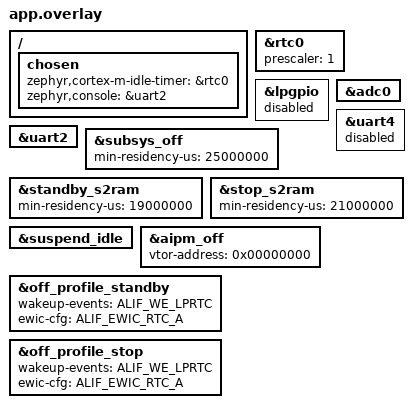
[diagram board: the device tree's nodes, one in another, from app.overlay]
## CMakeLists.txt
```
# Copyright (C) 2026 Alif Semiconductor - All Rights Reserved.
# Use, distribution and modification of this code is permitted under the
# terms stated in the Alif Semiconductor Software License Agreement
#
# You should have received a copy of the Alif Semiconductor Software
# License Agreement with this file. If not, please write to:
# contact@alifsemi.com, or visit: https://alifsemi.com/license

cmake_minimum_required(VERSION 3.20.0)
find_package(Zephyr REQUIRED HINTS $ENV{ZEPHYR_BASE})
project(adc_pm)

target_sources(app PRIVATE src/main.c)
```

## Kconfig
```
# Copyright (C) 2026 Alif Semiconductor - All Rights Reserved.
# Use, distribution and modification of this code is permitted under the
# terms stated in the Alif Semiconductor Software License Agreement
#
# You should have received a copy of the Alif Semiconductor Software
# License Agreement with this file. If not, please write to:
# contact@alifsemi.com, or visit: https://alifsemi.com/license

mainmenu "Alif ADC Power Management Demo"

source "Kconfig.zephyr"
```

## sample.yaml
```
sample:
  name: Alif ADC Power Management Demo
  description: >
    Demonstrates Zephyr power management states (PM_STATE_RUNTIME_IDLE,
    PM_STATE_SUSPEND_TO_IDLE, PM_STATE_SUSPEND_TO_RAM, PM_STATE_SOFT_OFF)
    for Alif RTSS cores with ADC12 temperature-sensor conversions between
    PM state transitions. PM states exercised are selected via build
    snippets: adc-pm-s2ram-tcm (HE TCM retention) and adc-pm-mram
    (MRAM boot SOFT_OFF, HE or HP).
common:
  tags:
    - power
    - pm
    - adc
    - counter
    - rtc
    - drivers
  filter: SOC_FAMILY_ENSEMBLE or SOC_FAMILY_BALLETTO
  harness: console
  harness_config:
    type: multi_line
    regex:
      - "ADC PM demo"
      - "POWER STATE SEQUENCE"
tests:
  sample.drivers.adc.pm.s2ram_tcm:
    platform_allow:
      - alif_e7_dk_rtss_he
      - alif_e8_dk_rtss_he
      - alif_e1c_dk_rtss_he
      - alif_b1_dk_rtss_he
    integration_platforms:
      - alif_e7_dk_rtss_he
    depends_on:
      - counter
      - adc
    extra_args:
      - SNIPPET=adc-pm-s2ram-tcm
  sample.drivers.adc.pm.mram:
    platform_allow:
      - alif_e7_dk_rtss_he
      - alif_e7_dk_rtss_hp
      - alif_e8_dk_rtss_he
      - alif_e8_dk_rtss_hp
      - alif_e1c_dk_rtss_he
      - alif_b1_dk_rtss_he
    integration_platforms:
      - alif_e7_dk_rtss_he
      - alif_e7_dk_rtss_hp
    depends_on:
      - counter
      - adc
    extra_args:
      - SNIPPET=adc-pm-mram
```

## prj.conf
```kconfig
# Copyright (C) 2026 Alif Semiconductor - All Rights Reserved.
# Use, distribution and modification of this code is permitted under the
# terms stated in the Alif Semiconductor Software License Agreement
#
# You should have received a copy of the Alif Semiconductor Software
# License Agreement with this file. If not, please write to:
# contact@alifsemi.com, or visit: https://alifsemi.com/license

CONFIG_ADC=y
CONFIG_USE_ALIF_HAL_ANALOG=y
CONFIG_CBPRINTF_FP_SUPPORT=y

CONFIG_PM=y
CONFIG_PM_DEVICE=y
CONFIG_POWER_DOMAIN=y
CONFIG_IDLE_STACK_SIZE=1024
CONFIG_SYS_CLOCK_TICKS_PER_SEC=1000

CONFIG_COUNTER=y

CONFIG_STDOUT_CONSOLE=y
CONFIG_PRINTK=y
CONFIG_ASSERT=y

CONFIG_LOG=y
CONFIG_LOG_DEFAULT_LEVEL=0
CONFIG_LOG_MODE_DEFERRED=y
CONFIG_LOG_PROCESS_THREAD_SLEEP_MS=5
CONFIG_LOG_BACKEND_UART=y
```

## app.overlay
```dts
/* Copyright (C) 2025 Alif Semiconductor - All Rights Reserved.
 * Use, distribution and modification of this code is permitted under the
 * terms stated in the Alif Semiconductor Software License Agreement
 *
 * You should have received a copy of the Alif Semiconductor Software
 * License Agreement with this file. If not, please write to:
 * contact@alifsemi.com, or visit: https://alifsemi.com/license
 *
 */

&rtc0 {
	prescaler = <1>;
	status = "okay";
};

&lpgpio {
	status = "disabled";
};

&adc0 {
	status = "okay";
};

&uart4 {
	status = "disabled";
};

&uart2 {
	status = "okay";
};

&subsys_off {
	min-residency-us = <25000000>;
	status = "okay";
};

&standby_s2ram {
	min-residency-us = <19000000>;
	status = "okay";
};

&stop_s2ram {
	min-residency-us = <21000000>;
	status = "okay";
};

&suspend_idle {
	status = "okay";
};

&aipm_off {
	vtor-address = <0x00000000>;
	status = "okay";
};

&off_profile_standby {
	status = "okay";
	wakeup-events = <ALIF_WE_LPRTC>;
	ewic-cfg = <ALIF_EWIC_RTC_A>;
};

&off_profile_stop {
	status = "okay";
	wakeup-events = <ALIF_WE_LPRTC>;
	ewic-cfg = <ALIF_EWIC_RTC_A>;
};

/ {
	chosen {
		zephyr,cortex-m-idle-timer = &rtc0;
		zephyr,console = &uart2;
	};
};
```

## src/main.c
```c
/* Copyright (C) 2026 Alif Semiconductor - All Rights Reserved.
 * Use, distribution and modification of this code is permitted under the
 * terms stated in the Alif Semiconductor Software License Agreement
 *
 * You should have received a copy of the Alif Semiconductor Software
 * License Agreement with this file. If not, please write to:
 * contact@alifsemi.com, or visit: https://alifsemi.com/license
 *
 */

 #include <stdio.h>
 #include <zephyr/kernel.h>
 #include <zephyr/device.h>
 #include <zephyr/devicetree.h>
 #include <zephyr/init.h>
 #include <zephyr/pm/pm.h>
 #include <zephyr/pm/policy.h>
 #include <zephyr/drivers/adc.h>
 #include <zephyr/drivers/counter.h>
 #include <zephyr/sys/util.h>
 #include <zephyr/logging/log.h>
 #include "temperature.h"

 LOG_MODULE_REGISTER(pm_adc, LOG_LEVEL_INF);

 /* Set to 1 to dump full NVIC ISPR state on wakeup */
 #define APP_PM_WAKEUP_DEBUG 0

 #define ADC_DEV_NODE DT_NODELABEL(adc0)

 #define ADC_CHANNEL_6			(0x06)
 #define ADC_UNMASK_CHANNEL_6		(1 << 6)

 /* Number of ADC conversions per PM phase */
 #define ADC_NUM_READS 3

 #if DT_NODE_HAS_COMPAT_STATUS(DT_NODELABEL(rtc0), snps_dw_apb_rtc, okay)
	 #define WAKEUP_SOURCE DT_NODELABEL(rtc0)
 #elif DT_NODE_HAS_COMPAT_STATUS(DT_NODELABEL(timer0), snps_dw_timers, okay)
	 #define WAKEUP_SOURCE DT_NODELABEL(timer0)
 #else
 #error "Wakeup Device not enabled in the dts"
 #endif

 /*
  * Sleep duration constants for each PM state.
  *
  * Upper bound: at 400 MHz, ticks-to-cycles calculation in the PM driver
  * overflows uint32 max for values > 10.7s (2^32 / 400). Deep-sleep durations
  * (S2RAM, SOFT_OFF) and overlay min-residency-us values must stay below this
  * ceiling. RUNTIME_IDLE may exceed it because deeper states are locked out
  * during that sleep (see app_pm_lock_sleep_states()).
  */
 /* Sleep duration for PM_STATE_RUNTIME_IDLE */
 #define RUNTIME_IDLE_SLEEP_USEC (18 * 1000 * 1000)
 /* Sleep duration for PM_STATE_SUSPEND_TO_IDLE */
 #define SUSPEND_IDLE_SLEEP_USEC (10 * 1000)
 /* Sleep duration for PM_STATE_SUSPEND_TO_RAM substate 0 (STANDBY) */
 #define S2RAM_STANDBY_SLEEP_USEC (6 * 1000 * 1000)
 /* Sleep duration for PM_STATE_SUSPEND_TO_RAM substate 1 (STOP) */
 #define S2RAM_STOP_SLEEP_USEC (9 * 1000 * 1000)
 /* Sleep duration for PM_STATE_SOFT_OFF */
 #define SOFT_OFF_SLEEP_USEC (10 * 1000 * 1000)

 /*
  * MRAM base address - used to determine boot location
  * TCM boot: VTOR = 0x0
  * MRAM boot: VTOR >= 0x80000000
  */
 #define MRAM_BASE_ADDRESS 0x80000000

 #define IS_BOOTING_FROM_MRAM() (SCB->VTOR >= MRAM_BASE_ADDRESS)

 /*
  * True when the DTS chosen zephyr,sram points at sram0. The snippet overlay
  * is responsible for ensuring SRAM0 has retention support on the target board.
  */
 #if DT_NODE_EXISTS(DT_NODELABEL(sram0)) && DT_HAS_CHOSEN(zephyr_sram)
 #define IS_SRAM0_CONFIGURED_AS_RAM() \
	 DT_SAME_NODE(DT_CHOSEN(zephyr_sram), DT_NODELABEL(sram0))
 #else
 #define IS_SRAM0_CONFIGURED_AS_RAM() 0
 #endif

 /*
  * S2RAM_SUPPORTED — retention-capable sleep is possible when:
  *   - SRAM0 is the configured data RAM (HE or HP, E8 only), OR
  *   - HE core booting from TCM (TCM has hardware retention)
  *
  * SOFT_OFF_SUPPORTED — mutually exclusive with S2RAM: used when no
  * retained RAM is available (HP-TCM, HE-MRAM boot without SRAM0).
  */
 #define S2RAM_SUPPORTED \
	 (IS_SRAM0_CONFIGURED_AS_RAM() || \
	  (IS_ENABLED(CONFIG_RTSS_HE) && !IS_BOOTING_FROM_MRAM()))

 #define SOFT_OFF_SUPPORTED (!S2RAM_SUPPORTED)

 /* Validate ordering of deep-sleep durations at compile time */
 BUILD_ASSERT(S2RAM_STOP_SLEEP_USEC > S2RAM_STANDBY_SLEEP_USEC,
	 "STOP sleep duration must be greater than STANDBY sleep duration");
 BUILD_ASSERT(SOFT_OFF_SLEEP_USEC > S2RAM_STOP_SLEEP_USEC,
	 "SOFT_OFF sleep duration must be greater than STOP sleep duration");

 /**
  * Helper function to lock/unlock deeper power states.
  * @param lock true → lock all deep states (allow RUNTIME_IDLE only)
  *             false → unlock the applicable state; keep the other locked
  */
 static void app_pm_lock_deeper_states(bool lock)
 {
	 if (lock) {
		 pm_policy_state_lock_get(PM_STATE_SUSPEND_TO_RAM, PM_ALL_SUBSTATES);
		 pm_policy_state_lock_get(PM_STATE_SOFT_OFF,       PM_ALL_SUBSTATES);
	 } else {
		 pm_policy_state_lock_put(PM_STATE_SOFT_OFF,       PM_ALL_SUBSTATES);
		 pm_policy_state_lock_put(PM_STATE_SUSPEND_TO_RAM, PM_ALL_SUBSTATES);
	 }
 }

 /*
  * Lock every PM sleep state deeper than RUNTIME_IDLE. Intended for use around
  * ADC conversions and around any sleep call the app makes where an accidental
  * upgrade to a deeper state must be prevented.
  *
  * ADC IRQs sit outside the IWIC wakeup range, so SUSPEND_TO_IDLE must not be
  * entered while a conversion is in progress.
  */
 static void app_pm_lock_sleep_states(bool lock)
 {
	 if (lock) {
		 pm_policy_state_lock_get(PM_STATE_SUSPEND_TO_IDLE, PM_ALL_SUBSTATES);
		 pm_policy_state_lock_get(PM_STATE_SUSPEND_TO_RAM,  PM_ALL_SUBSTATES);
		 pm_policy_state_lock_get(PM_STATE_SOFT_OFF,        PM_ALL_SUBSTATES);
	 } else {
		 pm_policy_state_lock_put(PM_STATE_SOFT_OFF,        PM_ALL_SUBSTATES);
		 pm_policy_state_lock_put(PM_STATE_SUSPEND_TO_RAM,  PM_ALL_SUBSTATES);
		 pm_policy_state_lock_put(PM_STATE_SUSPEND_TO_IDLE, PM_ALL_SUBSTATES);
	 }
 }

 #if !defined(CONFIG_CORTEX_M_SYSTICK_LPM_TIMER_COUNTER)
 static volatile uint32_t alarm_cb_status;
 static void alarm_callback_fn(const struct device *wakeup_dev,
				 uint8_t chan_id, uint32_t ticks,
				 void *user_data)
 {
	 LOG_DBG("%s: Alarm triggered", wakeup_dev->name);
	 alarm_cb_status = 1;
 }
 #endif

 static int app_enter_normal_sleep(uint32_t sleep_usec)
 {
 #if defined(CONFIG_CORTEX_M_SYSTICK_LPM_TIMER_COUNTER)
	 k_sleep(K_USEC(sleep_usec));
 #else
	 const struct device *const wakeup_dev = DEVICE_DT_GET(WAKEUP_SOURCE);
	 struct counter_alarm_cfg alarm_cfg = {0};
	 int ret;

	 alarm_cfg.flags = 0;
	 alarm_cfg.ticks = counter_us_to_ticks(wakeup_dev, sleep_usec);
	 alarm_cfg.callback = alarm_callback_fn;
	 alarm_cfg.user_data = &alarm_cfg;

	 ret = counter_set_channel_alarm(wakeup_dev, 0, &alarm_cfg);
	 if (ret) {
		 LOG_ERR("Could not set the alarm");
		 return ret;
	 }
	 LOG_DBG("Set alarm for %u microseconds", sleep_usec);

	 k_sleep(K_USEC(sleep_usec));

	 if (!alarm_cb_status) {
		 return -1;
	 }
	 alarm_cb_status = 0;

 #endif
	 return 0;
 }

 static int app_enter_deep_sleep(uint32_t sleep_usec)
 {
 #if defined(CONFIG_CORTEX_M_SYSTICK_LPM_TIMER_COUNTER)
	 /*
	  * Set a delay more than the min-residency-us configured so that
	  * the sub-system will go to OFF state.
	  */
	 k_sleep(K_USEC(sleep_usec));
 #else
	 const struct device *const wakeup_dev = DEVICE_DT_GET(WAKEUP_SOURCE);
	 struct counter_alarm_cfg alarm_cfg = {0};
	 int ret;
	 /*
	  * Set the alarm and delay so that idle thread can run
	  */
	 alarm_cfg.ticks = counter_us_to_ticks(wakeup_dev, sleep_usec);
	 ret = counter_set_channel_alarm(wakeup_dev, 0, &alarm_cfg);
	 if (ret) {
		 LOG_ERR("Failed to set the alarm (err %d)", ret);
		 return ret;
	 }

	 LOG_DBG("Set alarm for %u microseconds", sleep_usec);
	 /*
	  * Wait for the alarm to trigger. The idle thread will
	  * take care of entering the deep sleep state via PM framework.
	  */
	 k_sleep(K_USEC(sleep_usec));
 #endif

	 return 0;
 }

 static uint32_t adc_buffer[1];
 static uint32_t m_samplings_done;
 static uint8_t comparator;

 enum adc_action adc_call_back(const struct device *dev,
				 const struct adc_sequence *sequence,
				 uint16_t sampling_index)
 {
	 ARG_UNUSED(dev);
	 ARG_UNUSED(sequence);
	 ARG_UNUSED(sampling_index);

	 ++m_samplings_done;

	 if (m_samplings_done < 2) {
		 return ADC_ACTION_REPEAT;
	 }

	 return ADC_ACTION_FINISH;
 }

 /*
  * Re-setup the TSENS channel and take one conversion. Channel setup is
  * repeated after each resume because adc_hw_init() rebuilds analog state.
  */
 static int adc_read_once(const struct device *adc_dev)
 {
	 struct adc_sequence_options adc_seq_options = {
		 .callback = adc_call_back,
		 .user_data = &comparator,
	 };
	 struct adc_channel_cfg channel_cfg = {
		 .differential = 0,
		 .channel_id = ADC_CHANNEL_6,
	 };
	 struct adc_sequence sequence = {
		 .options = &adc_seq_options,
		 .buffer = adc_buffer,
		 .buffer_size = sizeof(adc_buffer),
		 .channels = ADC_UNMASK_CHANNEL_6,
	 };
	 float temp;
	 int ret;

	 m_samplings_done = 0;

	 ret = adc_channel_setup(adc_dev, &channel_cfg);
	 if (ret) {
		 LOG_ERR("Unable to set up ADC channel %u (err %d)",
			 channel_cfg.channel_id, ret);
		 return ret;
	 }

	 ret = adc_read(adc_dev, &sequence);
	 if (ret) {
		 LOG_ERR("ADC read failed (err %d)", ret);
		 return ret;
	 }

	 temp = get_temperature(adc_buffer[0]);
	 if (temp == -1) {
		 LOG_INF("ADC raw=0x%X (temperature outside range)", adc_buffer[0]);
	 } else {
		 LOG_INF("ADC raw=0x%X temp=%0.1f C", adc_buffer[0], (double)temp);
	 }

	 return 0;
 }

 /*
  * Run a short ADC conversion burst around one PM phase. Sleep states deeper
  * than RUNTIME_IDLE are locked while ADC is active so ADC IRQs outside the
  * IWIC wakeup range cannot be lost in SUSPEND_TO_IDLE.
  */
 static void adc_demo_run(const struct device *adc_dev, const char *phase_label)
 {
	 bool success = true;

	 app_pm_lock_sleep_states(true);
	 LOG_INF("[ADC Demo] %s", phase_label);

	 for (uint32_t i = 0; i < ADC_NUM_READS; i++) {
		 LOG_INF("ADC read iter= %u", i + 1);
		 if (adc_read_once(adc_dev) < 0) {
			 LOG_ERR("Stopping ADC conversions due to error");
			 success = false;
			 break;
		 }
		 k_msleep(100);
	 }

	 if (success) {
		 LOG_INF("ADC conversion Successfully Completed");
	 }

	 app_pm_lock_sleep_states(false);
 }

 /* PM state name lookup for notifier logging */
 static const char * const pm_state_names[] = {
	 [PM_STATE_ACTIVE]          = "ACTIVE",
	 [PM_STATE_RUNTIME_IDLE]    = "RUNTIME_IDLE",
	 [PM_STATE_SUSPEND_TO_IDLE] = "SUSPEND_TO_IDLE",
	 [PM_STATE_STANDBY]         = "STANDBY",
	 [PM_STATE_SUSPEND_TO_RAM]  = "SUSPEND_TO_RAM",
	 [PM_STATE_SUSPEND_TO_DISK] = "SUSPEND_TO_DISK",
	 [PM_STATE_SOFT_OFF]        = "SOFT_OFF",
 };

 #define PM_STATE_STR(s) \
	 ((s) < ARRAY_SIZE(pm_state_names) ? pm_state_names[(s)] : "UNKNOWN")

 static void pm_notify_entry(enum pm_state state)
 {
	 const struct pm_state_info *info = pm_state_next_get(0);
	 uint8_t substate_id = info ? info->substate_id : 0U;

	 LOG_INF("PM enter: %s (substate %u)", PM_STATE_STR(state), substate_id);
 }

 /*
  * With CONFIG_LOG_MODE_DEFERRED, LOG_INF here only writes to the ring buffer
  * — no UART access — so this is safe even before devices are resumed.
  */
 static void pm_notify_pre_resume(enum pm_state state)
 {
	 const struct pm_state_info *info = pm_state_next_get(0);
	 uint8_t substate_id = info ? info->substate_id : 0U;
	 uint32_t active_exc = SCB->ICSR & SCB_ICSR_VECTACTIVE_Msk;

	 if (active_exc >= 16U) {
		 LOG_INF("PM wakeup: %s (substate %u) IRQ %u",
			 PM_STATE_STR(state), substate_id, active_exc - 16U);
	 } else if (active_exc != 0U) {
		 LOG_INF("PM wakeup: %s (substate %u) exception %u",
			 PM_STATE_STR(state), substate_id, active_exc);
	 } else {
		 LOG_INF("PM wakeup: %s (substate %u)",
			 PM_STATE_STR(state), substate_id);
	 }
 #if APP_PM_WAKEUP_DEBUG
	 for (int i = 0; i < 16; i++) {
		 if (NVIC->ISPR[i]) {
			 LOG_INF("PM wakeup: NVIC ISPR[%d] = 0x%08x", i, NVIC->ISPR[i]);
		 }
	 }
 #endif
 }

 static void pm_notify_exit(enum pm_state state)
 {
	 const struct pm_state_info *info = pm_state_next_get(0);
	 uint8_t substate_id = info ? info->substate_id : 0U;

	 LOG_INF("PM exit:  %s (substate %u)", PM_STATE_STR(state), substate_id);
 }

 static struct pm_notifier app_pm_notifier = {
	 .state_entry       = pm_notify_entry,
	 .pre_device_resume = pm_notify_pre_resume,
	 .state_exit        = pm_notify_exit,
 };

 int main(void)
 {
	 const struct device *const cons = DEVICE_DT_GET(DT_CHOSEN(zephyr_console));
	 const struct device *const wakeup_dev = DEVICE_DT_GET(WAKEUP_SOURCE);
	 const struct device *const adc_dev = DEVICE_DT_GET(ADC_DEV_NODE);
	 int ret;

	 __ASSERT(device_is_ready(cons), "%s: device not ready", cons->name);
	 __ASSERT(device_is_ready(wakeup_dev), "%s: device not ready", wakeup_dev->name);
	 __ASSERT(device_is_ready(adc_dev), "%s: device not ready", adc_dev->name);

	 pm_notifier_register(&app_pm_notifier);

	 if (S2RAM_SUPPORTED) {
		 LOG_INF("%s (S2RAM): ADC PM demo "
			 "(RUNTIME_IDLE, SUSPEND_TO_IDLE, S2RAM STANDBY, S2RAM STOP)",
			 CONFIG_BOARD);
	 } else {
		 LOG_INF("%s (SOFT_OFF): ADC PM demo "
			 "(RUNTIME_IDLE, SUSPEND_TO_IDLE, SOFT_OFF)",
			 CONFIG_BOARD);
	 }

	 ret = counter_start(wakeup_dev);
	 __ASSERT(!ret || ret == -EALREADY, "Failed to start counter (err %d)", ret);

	 LOG_INF("POWER STATE SEQUENCE:");
	 LOG_INF("  1. PM_STATE_RUNTIME_IDLE");
	 LOG_INF("  2. PM_STATE_SUSPEND_TO_IDLE");
	 if (S2RAM_SUPPORTED) {
		 LOG_INF("  3. PM_STATE_SUSPEND_TO_RAM (substate 0: STANDBY)");
		 LOG_INF("  4. PM_STATE_SUSPEND_TO_RAM (substate 1: STOP)");
	 } else {
		 LOG_INF("  3. PM_STATE_SOFT_OFF");
	 }

	 adc_demo_run(adc_dev, "before RUNTIME_IDLE");

	 LOG_INF("Enter RUNTIME_IDLE sleep for (%d microseconds)", RUNTIME_IDLE_SLEEP_USEC);
	 app_pm_lock_sleep_states(true);
	 ret = app_enter_normal_sleep(RUNTIME_IDLE_SLEEP_USEC);
	 app_pm_lock_sleep_states(false);
	 __ASSERT(ret == 0, "Could not enter RUNTIME_IDLE sleep (err %d)", ret);

	 LOG_INF("Exited from RUNTIME_IDLE sleep");

 #if defined(CONFIG_CORTEX_M_SYSTICK_LPM_TIMER_COUNTER)
	 LOG_INF("Request SUSPEND_TO_IDLE for %d us", SUSPEND_IDLE_SLEEP_USEC);
	 app_pm_lock_deeper_states(true);
	 k_sleep(K_USEC(SUSPEND_IDLE_SLEEP_USEC));
	 app_pm_lock_deeper_states(false);
	 adc_demo_run(adc_dev, "after SUSPEND_TO_IDLE");
 #else
	 /* Lock SUSPEND_TO_IDLE when LPM timer support is not configured */
	 pm_policy_state_lock_get(PM_STATE_SUSPEND_TO_IDLE, PM_ALL_SUBSTATES);
	 LOG_INF("PM_STATE_SUSPEND_TO_IDLE (skipped - LPM timer not enabled)");
 #endif

	 if (S2RAM_SUPPORTED) {
		 LOG_INF("Request S2RAM STANDBY for %d us", S2RAM_STANDBY_SLEEP_USEC);
		 ret = app_enter_deep_sleep(S2RAM_STANDBY_SLEEP_USEC);
		 __ASSERT(ret == 0, "Could not enter PM_STATE_SUSPEND_TO_RAM (err %d)", ret);

		 adc_demo_run(adc_dev, "after S2RAM STANDBY");

		 LOG_INF("Request S2RAM STOP for %d us", S2RAM_STOP_SLEEP_USEC);
		 ret = app_enter_deep_sleep(S2RAM_STOP_SLEEP_USEC);
		 __ASSERT(ret == 0, "Could not enter PM_STATE_SUSPEND_TO_RAM (err %d)", ret);

		 adc_demo_run(adc_dev, "after S2RAM STOP");
	 }

	 if (SOFT_OFF_SUPPORTED) {
		 LOG_INF("Request SOFT_OFF for %d us (no retention - system resets on wakeup)",
			 SOFT_OFF_SLEEP_USEC);
		 ret = app_enter_deep_sleep(SOFT_OFF_SLEEP_USEC);
		 __ASSERT(ret == 0, "Could not enter PM_STATE_SOFT_OFF (err %d)", ret);

		 /* Should never reach here - SOFT_OFF causes full reset on wakeup */
		 LOG_ERR("ERROR: Resumed after PM_STATE_SOFT_OFF - this should not happen!");
		 __ASSERT(false, "PM_STATE_SOFT_OFF should have caused a reset");
	 }

	 LOG_INF("=== ADC PM SEQUENCE COMPLETED ===");

	 app_pm_lock_deeper_states(true);
	 /* Demo complete — prevent SUSPEND_TO_IDLE so the idle spin stays in RUNTIME_IDLE */
	 pm_policy_state_lock_get(PM_STATE_SUSPEND_TO_IDLE, PM_ALL_SUBSTATES);

	 while (true) {
		 /* spin here */
		 k_sleep(K_SECONDS(1));
	 }

	 return 0;
 }
```

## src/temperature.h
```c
/* Copyright (C) 2024 Alif Semiconductor - All Rights Reserved.
 * Use, distribution and modification of this code is permitted under the
 * terms stated in the Alif Semiconductor Software License Agreement
 *
 * You should have received a copy of the Alif Semiconductor Software
 * License Agreement with this file. If not, please write to:
 * contact@alifsemi.com, or visit: https://alifsemi.com/license
 *
 */

#ifndef TEMPERATURE_H_
#define TEMPERATURE_H_

#include <stdint.h>
#include <zephyr/sys/util.h>

/* Define a 2D array to store the ADC values and corresponding temperatures */
static const float tempData[][2] = {
	{918, -40.0},
	{919, -39.6},
	{920, -39.2},
	{921, -38.8},
	{922, -38.4},
	{923, -38.0},
	{924, -37.6},
	{925, -37.2},
	{926, -36.8},
	{927, -36.4},
	{928, -36.0},
	{929, -35.6},
	{930, -35.2},
	{931, -34.8},
	{932, -34.4},
	{933, -34.0},
	{934, -33.6},
	{935, -33.2},
	{936, -32.8},
	{937, -32.4},
	{938, -32.0},
	{939, -31.6},
	{940, -31.2},
	{941, -30.8},
	{942, -30.4},
	{943, -30.0},
	{944, -29.8},
	{945, -29.7},
	{946, -29.5},
	{947, -29.3},
	{948, -29.2},
	{949, -29.0},
	{950, -28.8},
	{951, -28.7},
	{952, -28.5},
	{953, -28.3},
	{954, -28.2},
	{955, -28.0},
	{956, -27.8},
	{957, -27.7},
	{958, -27.5},
	{959, -27.3},
	{960, -27.2},
	{961, -27.0},
	{962, -26.8},
	{963, -26.7},
	{964, -26.5},
	{965, -26.3},
	{966, -26.2},
	{967, -26.0},
	{968, -25.8},
	{969, -25.7},
	{970, -25.5},
	{971, -25.3},
	{972, -25.2},
	{973, -25.0},
	{974, -24.8},
	{975, -24.7},
	{976, -24.5},
	{977, -24.3},
	{978, -24.2},
	{979, -24.0},
	{980, -23.8},
	{981, -23.7},
	{982, -23.5},
	{983, -23.3},
	{984, -23.2},
	{985, -23.0},
	{986, -22.8},
	{987, -22.7},
	{988, -22.5},
	{989, -22.3},
	{990, -22.2},
	{991, -22.0},
	{992, -21.8},
	{993, -21.7},
	{994, -21.5},
	{995, -21.3},
	{996, -21.2},
	{997, -21.0},
	{998, -20.8},
	{999, -20.7},
	{1000, -20.5},
	{1001, -20.3},
	{1002, -20.2},
	{1003, -20.0},
	{1004, -19.2},
	{1005, -18.5},
	{1006, -17.7},
	{1007, -16.9},
	{1008, -16.2},
	{1009, -15.4},
	{1010, -14.6},
	{1011, -13.8},
	{1012, -13.1},
	{1013, -12.3},
	{1014, -11.5},
	{1015, -10.8},
	{1016, -10.0},
	{1017, -9.4},
	{1018, -8.8},
	{1019, -8.1},
	{1020, -7.5},
	{1021, -6.9},
	{1022, -6.3},
	{1023, -5.6},
	{1024, -5.0},
	{1025, -4.4},
	{1026, -3.8},
	{1027, -3.1},
	{1028, -2.5},
	{1029, -1.9},
	{1030, -1.3},
	{1031, -0.6},
	{1032, 0.0},
	{1033, 0.7},
	{1034, 1.3},
	{1035, 2.0},
	{1036, 2.7},
	{1037, 3.3},
	{1038, 4.0},
	{1039, 4.7},
	{1040, 5.3},
	{1041, 6.0},
	{1042, 6.7},
	{1043, 7.3},
	{1044, 8.0},
	{1045, 8.7},
	{1046, 9.3},
	{1047, 10.0},
	{1048, 10.4},
	{1049, 10.9},
	{1050, 11.3},
	{1051, 11.7},
	{1052, 12.2},
	{1053, 12.6},
	{1054, 13.0},
	{1055, 13.5},
	{1056, 13.9},
	{1057, 14.3},
	{1058, 14.8},
	{1059, 15.2},
	{1060, 15.7},
	{1061, 16.1},
	{1062, 16.5},
	{1063, 17.0},
	{1064, 17.4},
	{1065, 17.8},
	{1066, 18.3},
	{1067, 18.7},
	{1068, 19.1},
	{1069, 19.6},
	{1070, 20.0},
	{1071, 20.2},
	{1072, 20.3},
	{1073, 20.5},
	{1074, 20.7},
	{1075, 20.9},
	{1076, 21.0},
	{1077, 21.2},
	{1078, 21.4},
	{1079, 21.6},
	{1080, 21.7},
	{1081, 21.9},
	{1082, 22.1},
	{1083, 22.2},
	{1084, 22.4},
	{1085, 22.6},
	{1086, 22.8},
	{1087, 22.9},
	{1088, 23.1},
	{1089, 23.3},
	{1090, 23.4},
	{1091, 23.6},
	{1092, 23.8},
	{1093, 24.0},
	{1094, 24.1},
	{1095, 24.3},
	{1096, 24.5},
	{1097, 24.7},
	{1098, 24.8},
	{1099, 25.0},
	{1100, 25.2},
	{1101, 25.3},
	{1102, 25.5},
	{1103, 25.7},
	{1104, 25.9},
	{1105, 26.0},
	{1106, 26.2},
	{1107, 26.4},
	{1108, 26.6},
	{1109, 26.7},
	{1110, 26.9},
	{1111, 27.1},
	{1112, 27.2},
	{1113, 27.4},
	{1114, 27.6},
	{1115, 27.8},
	{1116, 27.9},
	{1117, 28.1},
	{1118, 28.3},
	{1119, 28.4},
	{1120, 28.6},
	{1121, 28.8},
	{1122, 29.0},
	{1123, 29.1},
	{1124, 29.3},
	{1125, 29.5},
	{1126, 29.7},
	{1127, 29.8},
	{1128, 30.0},
	{1129, 30.3},
	{1130, 30.5},
	{1131, 30.8},
	{1132, 31.0},
	{1133, 31.3},
	{1134, 31.5},
	{1135, 31.8},
	{1136, 32.0},
	{1137, 32.3},
	{1138, 32.5},
	{1139, 32.8},
	{1140, 33.0},
	{1141, 33.3},
	{1142, 33.5},
	{1143, 33.8},
	{1144, 34.0},
	{1145, 34.3},
	{1146, 34.5},
	{1147, 34.8},
	{1148, 35.0},
	{1149, 35.3},
	{1150, 35.5},
	{1151, 35.8},
	{1152, 36.0},
	{1153, 36.3},
	{1154, 36.5},
	{1155, 36.8},
	{1156, 37.0},
	{1157, 37.3},
	{1158, 37.5},
	{1159, 37.8},
	{1160, 38.0},
	{1161, 38.3},
	{1162, 38.5},
	{1163, 38.8},
	{1164, 39.0},
	{1165, 39.3},
	{1166, 39.5},
	{1167, 39.8},
	{1168, 40.0},
	{1169, 40.5},
	{1170, 40.9},
	{1171, 41.4},
	{1172, 41.8},
	{1173, 42.3},
	{1174, 42.7},
	{1175, 43.2},
	{1176, 43.6},
	{1177, 44.1},
	{1178, 44.5},
	{1179, 45.0},
	{1180, 45.5},
	{1181, 45.9},
	{1182, 46.4},
	{1183, 46.8},
	{1184, 47.3},
	{1185, 47.7},
	{1186, 48.2},
	{1187, 48.6},
	{1188, 49.1},
	{1189, 49.5},
	{1190, 50.0},
	{1191, 50.2},
	{1192, 50.3},
	{1193, 50.5},
	{1194, 50.7},
	{1195, 50.9},
	{1196, 51.0},
	{1197, 51.2},
	{1198, 51.4},
	{1199, 51.6},
	{1200, 51.7},
	{1201, 51.9},
	{1202, 52.1},
	{1203, 52.2},
	{1204, 52.4},
	{1205, 52.6},
	{1206, 52.8},
	{1207, 52.9},
	{1208, 53.1},
	{1209, 53.3},
	{1210, 53.4},
	{1211, 53.6},
	{1212, 53.8},
	{1213, 54.0},
	{1214, 54.1},
	{1215, 54.3},
	{1216, 54.5},
	{1217, 54.7},
	{1218, 54.8},
	{1219, 55.0},
	{1220, 55.2},
	{1221, 55.3},
	{1222, 55.5},
	{1223, 55.7},
	{1224, 55.9},
	{1225, 56.0},
	{1226, 56.2},
	{1227, 56.4},
	{1228, 56.6},
	{1229, 56.7},
	{1230, 56.9},
	{1231, 57.1},
	{1232, 57.2},
	{1233, 57.4},
	{1234, 57.6},
	{1235, 57.8},
	{1236, 57.9},
	{1237, 58.1},
	{1238, 58.3},
	{1239, 58.4},
	{1240, 58.6},
	{1241, 58.8},
	{1242, 59.0},
	{1243, 59.1},
	{1244, 59.3},
	{1245, 59.5},
	{1246, 59.7},
	{1247, 59.8},
	{1248, 60.0},
	{1249, 60.3},
	{1250, 60.7},
	{1251, 61.0},
	{1252, 61.3},
	{1253, 61.7},
	{1254, 62.0},
	{1255, 62.3},
	{1256, 62.7},
	{1257, 63.0},
	{1258, 63.3},
	{1259, 63.7},
	{1260, 64.0},
	{1261, 64.3},
	{1262, 64.7},
	{1263, 65.0},
	{1264, 65.3},
	{1265, 65.7},
	{1266, 66.0},
	{1267, 66.3},
	{1268, 66.7},
	{1269, 67.0},
	{1270, 67.3},
	{1271, 67.7},
	{1272, 68.0},
	{1273, 68.3},
	{1274, 68.7},
	{1275, 69.0},
	{1276, 69.3},
	{1277, 69.7},
	{1278, 70.0},
	{1279, 70.4},
	{1280, 70.9},
	{1281, 71.3},
	{1282, 71.7},
	{1283, 72.2},
	{1284, 72.6},
	{1285, 73.0},
	{1286, 73.5},
	{1287, 73.9},
	{1288, 74.3},
	{1289, 74.8},
	{1290, 75.2},
	{1291, 75.7},
	{1292, 76.1},
	{1293, 76.5},
	{1294, 77.0},
	{1295, 77.4},
	{1296, 77.8},
	{1297, 78.3},
	{1298, 78.7},
	{1299, 79.1},
	{1300, 79.6},
	{1301, 80.0},
	{1302, 80.5},
	{1303, 81.1},
	{1304, 81.6},
	{1305, 82.1},
	{1306, 82.6},
	{1307, 83.2},
	{1308, 83.7},
	{1309, 84.2},
	{1310, 84.7},
	{1311, 85.3},
	{1312, 85.8},
	{1313, 86.3},
	{1314, 86.8},
	{1315, 87.4},
	{1316, 87.9},
	{1317, 88.4},
	{1318, 88.9},
	{1319, 89.5},
	{1320, 90.0}
};

/*
 * @func : float get_temperature (uint32_t adc_value)
 * @brief: Converts the digital value into a temperature reading
 * @parameter[1] : adc_value  : The digital value obtained from TSENS conversion
 * @return   : temperature
 */
static float get_temperature(uint32_t adc_value)
{
	uint32_t i;
	const uint32_t last = ARRAY_SIZE(tempData) - 1;

	/* check for temperature operating range */
	if (adc_value < tempData[0][0] || (adc_value > tempData[last][0])) {
		return -1;
	}

	for (i = 0; i < ARRAY_SIZE(tempData); i++) {
		/* check if value matches with tempdata */
		if (adc_value == tempData[i][0]) {
			return tempData[i][1];
		}
	}

	return -1;
}
#endif /*TEMPERATURE_H_ */
```
